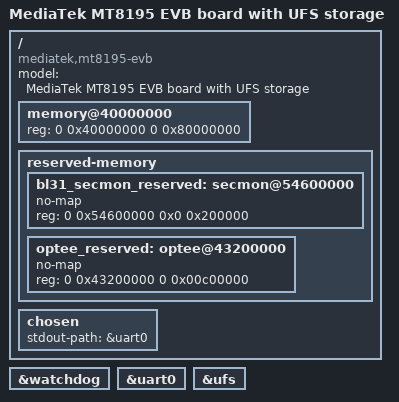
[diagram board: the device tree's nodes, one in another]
// SPDX-License-Identifier: GPL-2.0 OR MIT
/*
 * Copyright (C) 2021 BayLibre SAS.
 * Author: Fabien Parent <fparent@baylibre.com>
 */

/dts-v1/;

#include <config.h>
#include "mt8195.dtsi"

/ {
	model = "MediaTek MT8195 EVB board with UFS storage";
	compatible = "mediatek,mt8195-evb", "mediatek,mt8195";

	memory@40000000 {
		device_type = "memory";
		reg = <0 0x40000000 0 0x80000000>;
	};

	reserved-memory {
		#address-cells = <2>;
		#size-cells = <2>;
		ranges;

		/* 2 MiB reserved for ARM Trusted Firmware (BL31) */
		bl31_secmon_reserved: secmon@54600000 {
			no-map;
			reg = <0 0x54600000 0x0 0x200000>;
		};

		/* 12 MiB reserved for OP-TEE (BL32)
		 * +-----------------------+ 0x43e0_0000
		 * |      SHMEM 2MiB       |
		 * +-----------------------+ 0x43c0_0000
		 * |        | TA_RAM  8MiB |
		 * + TZDRAM +--------------+ 0x4340_0000
		 * |        | TEE_RAM 2MiB |
		 * +-----------------------+ 0x4320_0000
		 */
		optee_reserved: optee@43200000 {
			no-map;
			reg = <0 0x43200000 0 0x00c00000>;
		};
	};

	chosen {
		stdout-path = &uart0;
	};
};

&watchdog {
	status = "okay";
};

&uart0 {
	status = "okay";
};

&ufs {
	status = "okay";
};
